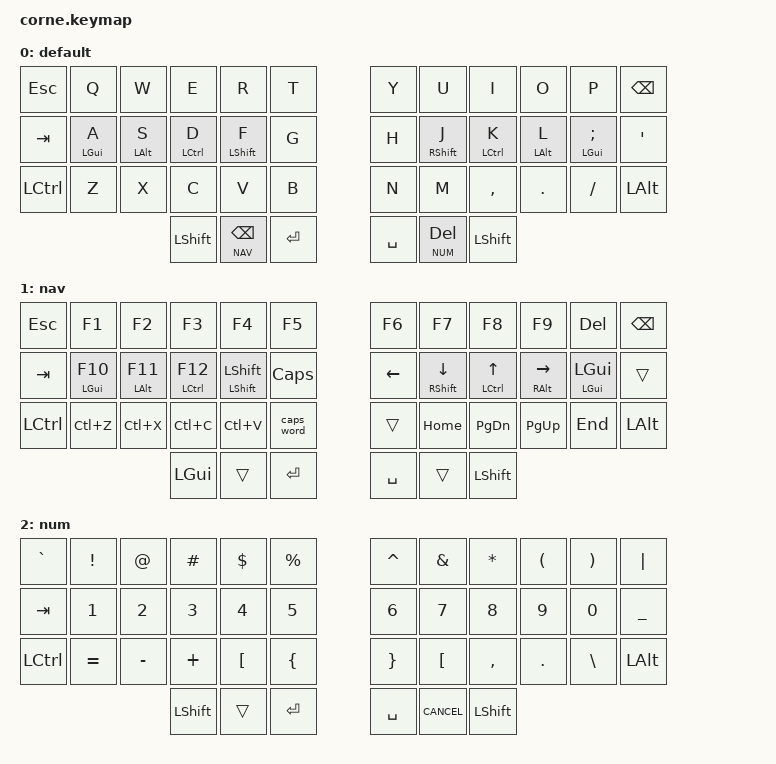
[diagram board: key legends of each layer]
/*
 * Copyright (c) 2020 The ZMK Contributors
 *
 * SPDX-License-Identifier: MIT
 */

#include <behaviors.dtsi>
#include <dt-bindings/zmk/keys.h>
#include <dt-bindings/zmk/bt.h>
#define _BT_SEL_KEYS_ &bt BT_SEL 0 &bt BT_SEL 1 &bt BT_SEL 2 &bt BT_SEL 3 &bt BT_CLR

#include "../zmk-nodefree-config/helper.h"
#include "../zmk-nodefree-config/keypos_def/keypos_42keys.h"
#include "../zmk-nodefree-config/international_chars/german.dtsi"

#define DEF 0
#define NAV 1
#define NUM 2
#define SYS 3

/*#include "combos.dtsi"  // requires layer aliases*/
/*#include "extra_keys.h"*/

/*layers and shortcuts*/
#define XXX &none
#define ___ &trans

/* Global settings */

#define QUICK_TAP_MS 175

&sk {  // sticky-key config
    release-after-ms = <900>;  // release after 0.6s
    quick-release;             // no double capitalization when rolling keys
};

&sl {  // sticky-layer config
    ignore-modifiers;          // allow chording sticky mods & layers
};

&lt {  // layer-tap config
    flavor = "balanced";
    tapping-term-ms = <200>;
    quick-tap-ms = <QUICK_TAP_MS>;
};

/*custom behaviors*/

// homerow mods
#define KEYS_L LT0 LT1 LT2 LT3 LT4 LT5 LM0 LM1 LM2 LM3 LM4 LM5 LB0 LB1 LB2 LB3 LB4 LB5  // left hand
#define KEYS_R RT0 RT1 RT2 RT3 RT4 RT5 RM0 RM1 RM2 RM3 RM4 RM5 RB0 RB1 RB2 RB3 RB4 RM5  // right hand
#define THUMBS LH2 LH1 LH0 RH0 RH1 RH2                                      // thumbs

#define MAKE_HRM(NAME, HOLD, TAP, TRIGGER_POS) \
    ZMK_BEHAVIOR(NAME, hold_tap, \
        flavor = "balanced"; \
        tapping-term-ms = <280>; \
        quick-tap-ms = <QUICK_TAP_MS>; \
        global-quick-tap-ms = <150>; \
        bindings = <HOLD>, <TAP>; \
        hold-trigger-key-positions = <TRIGGER_POS>; \
        hold-trigger-on-release; \
    )
MAKE_HRM(hml, &kp, &kp, KEYS_R THUMBS)  // left-hand HRMs
MAKE_HRM(hmr, &kp, &kp, KEYS_L THUMBS)  // right-hand HRMs

/*MAKE_HRM(hml_repeat, &kp, &key_repeat, KEYS_R THUMBS)  // used for HRM-combo*/
/*MAKE_HRM(hmr_lpar_lt, &kp, &lpar_lt, KEYS_L THUMBS)    // "    "   "   "*/
/*MAKE_HRM(hmr_rpar_gt, &kp, &rpar_gt, KEYS_L THUMBS)    // "    "   "   "*/


// tap: backspace | shift + tap: delete | hold: num layer
/*ZMK_BEHAVIOR(bs_del_num, mod_morph,*/
    /*bindings = <&lt NUM BSPC>, <&kp DEL>;*/
    /*mods = <(MOD_LSFT|MOD_RSFT)>;*/
/*)*/

/* Caps-word, num-word */

// tap: sticky-shift | shift + tap/ double-tap: caps-word | hold: shift
/*ZMK_BEHAVIOR(smart_shft, mod_morph,*/
    /*bindings = <&sk LSHFT>, <&caps_word>;*/
    /*mods = <(MOD_LSFT)>;*/
/*)*/
/*&caps_word {  // mods deactivate caps-word, requires PR #1451*/
    /*/delete-property/ ignore-modifiers;*/
/*};*/

// tap: num-word | double-tap: sticky num-layer | hold: num-layer
/*#define SMART_NUM &smart_num NUM 0*/
/*ZMK_BEHAVIOR(smart_num, hold_tap,*/
    /*flavor = "balanced";*/
    /*tapping-term-ms = <200>;*/
    /*quick-tap-ms = <QUICK_TAP_MS>;*/
    /*bindings = <&mo>, <&num_dance>;*/
/*)*/
/*ZMK_BEHAVIOR(num_dance, tap_dance,*/
    /*tapping-term-ms = <200>;*/
    /*bindings = <&num_word>, <&sl NUM>;  // reverse this for sticky-num on single tap*/
/*)*/
/*&num_word {  // num-word, requires PR #1451*/
    /*layers = <NUM>;*/
    /*continue-list = <BSPC DEL DOT COMMA PLUS MINUS STAR FSLH EQUAL>;*/
/*};*/

// Sticky layer + sticky shift (workaround for issue #1421)
/*ZMK_BEHAVIOR(sls, sticky_key,*/
    /*release-after-ms = <1000>;*/
    /*bindings = <&uc_shift>;*/
    /*ignore-modifiers;*/
/*)*/
/*ZMK_BEHAVIOR(uc_shift, macro,*/
    /*wait-ms = <0>;*/
    /*tap-ms = <1>;*/
    /*bindings = <&macro_press &mo UC &kp LSHFT>*/
             /*, <&macro_pause_for_release>*/
             /*, <&macro_release &mo UC &kp LSHFT>;*/
/*)*/

// Alt+Tab swapper, requires PR #1366
/*ZMK_BEHAVIOR(swapper, tri_state,*/
    /*bindings = <&kt LALT>, <&kp TAB>, <&kt LALT>;*/
    /*ignored-key-positions = <LT2>;*/
/*)*/

/*#undef COMBO_TERM*/
/*#define COMBO_TERM 40  // timeout of 40ms (default is 30ms if omitted)*/
/*ZMK_COMBO(combo_copy,   &kp LC(C),  LB2 LB3, ALL)  // Ctrl + C, active on all layers*/
/*ZMK_COMBO(combo_paste,  &kp LC(V),  LB1 LB2, ALL)  // Ctrl + V, active on all layers*/

/* Keymap */

ZMK_CONDITIONAL_LAYER(NAV NUM, SYS)  // NAV + SYM --> SYS

ZMK_LAYER(default,
     // ╭─────────────┬─────────────┬─────────────┬─────────────┬─────────────┬─────────────╮   ╭─────────────┬─────────────┬─────────────┬─────────────┬─────────────┬─────────────╮
          &kp ESC         &kp Q         &kp W         &kp E         &kp R           &kp T            &kp Y         &kp U         &kp I         &kp O         &kp P       &kp BSPC
     // ├─────────────┼─────────────┼─────────────┬─────────────┼─────────────┼─────────────┤   ├─────────────┬─────────────┼─────────────┼─────────────┼─────────────┼─────────────┤
          &kp TAB       &hml LGUI A   &hml LALT S   &hml LCTRL D  &hml LSHFT F     &kp G             &kp H     &hmr RSHFT J  &hmr LCTRL K  &hmr LALT L   &hmr LGUI SEMI  &kp SQT
     // ├─────────────┼─────────────┼─────────────┬─────────────┼─────────────┼─────────────┤   ├─────────────┬─────────────┼─────────────┼─────────────┼─────────────┼─────────────┤
          &kp LCTRL         &kp Z         &kp X         &kp C         &kp V        &kp B             &kp N         &kp M       &kp COMMA      &kp DOT      &kp FSLH      &kp LALT
     // ╰─────────────┼─────────────┼─────────────┬─────────────┼─────────────┼─────────────┤   ├─────────────┬─────────────┼─────────────┼─────────────┼─────────────┼─────────────┤
                                                   &kp LSHIFT    &lt NAV BSPC    &kp RET           &kp SPACE    &lt NUM DEL  &kp LSHIFT
     //                                           ╰─────────────┴─────────────┴─────────────╯   ╰─────────────┴─────────────┴─────────────╯
)

ZMK_LAYER(nav,
     // ╭─────────────┬─────────────┬─────────────┬─────────────┬─────────────┬─────────────╮   ╭─────────────┬─────────────┬─────────────┬─────────────┬─────────────┬─────────────╮
          &kp ESC         &kp F1        &kp F2       &kp F3         &kp F4        &kp F5            &kp F6        &kp F7        &kp F8        &kp F9         &kp DEL      &kp BSPC
     // ├─────────────┼─────────────┼─────────────┬─────────────┼─────────────┼─────────────┤   ├─────────────┬─────────────┼─────────────┼─────────────┼─────────────┼─────────────┤
          &kp TAB      &hml LGUI F10 &hml LALT F11 &hml LCTRL F12 &hml LSHFT LSHIFT &kp CAPS     &kp LEFT      &hmr RSHFT DOWN &hmr LCTRL UP &hmr RALT RIGHT &hmr LGUI LGUI   ___ 
     // ├─────────────┼─────────────┼─────────────┬─────────────┼─────────────┼─────────────┤   ├─────────────┬─────────────┼─────────────┼─────────────┼─────────────┼─────────────┤
          &kp LCTRL      &kp LC(Z)     &kp LC(X)    &kp LC(C)      &kp LC(V)    &caps_word             ___       &kp HOME    &kp PAGE_DOWN &kp PAGE_UP      &kp END      &kp LALT
     // ╰─────────────┼─────────────┼─────────────┬─────────────┼─────────────┼─────────────┤   ├─────────────┬─────────────┼─────────────┼─────────────┼─────────────┼─────────────┤
                                                     &kp LGUI         ___         &kp RET           &kp SPACE       ___       &kp LSHIFT
     //                                           ╰─────────────┴─────────────┴─────────────╯   ╰─────────────┴─────────────┴─────────────╯
)

ZMK_LAYER(num,
     // ╭─────────────┬─────────────┬─────────────┬─────────────┬─────────────┬─────────────╮   ╭─────────────┬─────────────┬─────────────┬─────────────┬─────────────┬─────────────╮
          &kp GRAVE      &kp EXCL      &kp AT        &kp HASH      &kp DLLR      &kp PRCNT         &kp CARET     &kp AMPS   &kp ASTRK       &kp LPAR      &kp RPAR       &kp PIPE
     // ├─────────────┼─────────────┼─────────────┬─────────────┼─────────────┼─────────────┤   ├─────────────┬─────────────┼─────────────┼─────────────┼─────────────┼─────────────┤
          &kp TAB       &kp N1           &kp N2       &kp N3        &kp N4        &kp N5             &kp N6       &kp N7        &kp N8        &kp N9       &kp N0        &kp UNDER
     // ├─────────────┼─────────────┼─────────────┬─────────────┼─────────────┼─────────────┤   ├─────────────┬─────────────┼─────────────┼─────────────┼─────────────┼─────────────┤
          &kp LCTRL    &kp EQUAL       &kp MINUS    &kp PLUS       &kp LBKT     &kp LBRC          &kp RBRC      &kp LBKT      &kp COMMA      &kp DOT      &kp BSLH      &kp LALT
     // ╰─────────────┼─────────────┼─────────────┬─────────────┼─────────────┼─────────────┤   ├─────────────┬─────────────┼─────────────┼─────────────┼─────────────┼─────────────┤
                                                   &kp LSHIFT         ___        &kp RET           &kp SPACE      CANCEL      &kp LSHIFT
     //                                           ╰─────────────┴─────────────┴─────────────╯   ╰─────────────┴─────────────┴─────────────╯
)

/*ZMK_LAYER(sys,*/
     /*// ╭─────────────┬─────────────┬─────────────┬─────────────┬─────────────┬─────────────╮   ╭─────────────┬─────────────┬─────────────┬─────────────┬─────────────┬─────────────╮*/
          /*&kp ESC      &bt BT_SEL 0  &bt BT_SEL 1  &bt BT_SEL 2       ___          ___               ___           ___            ___          ___           ___           ___*/
     /*// ├─────────────┼─────────────┼─────────────┬─────────────┼─────────────┼─────────────┤   ├─────────────┬─────────────┼─────────────┼─────────────┼─────────────┼─────────────┤*/
          /*&sys_reset    &bootloader     ___           ___             ___          ___               ___           ___            ___       &kp K_LOCK    &bootloader   &sys_reset*/
     /*// ├─────────────┼─────────────┼─────────────┬─────────────┼─────────────┼─────────────┤   ├─────────────┬─────────────┼─────────────┼─────────────┼─────────────┼─────────────┤*/
             /*___       &out OUT_TOG     ___           ___             ___          ___           &kp LC(LS(M))  &kp C_MUTE    &kp C_VOL_DN  &kp C_VOL_UP    ___             ___*/
     /*// ╰─────────────┼─────────────┼─────────────┬─────────────┼─────────────┼─────────────┤   ├─────────────┬─────────────┼─────────────┼─────────────┼─────────────┼─────────────┤*/
                                                   /*&kp LSHIFT         ___        &kp RET           &kp SPACE        ___       &kp LSHIFT*/
     /*//                                           ╰─────────────┴─────────────┴─────────────╯   ╰─────────────┴─────────────┴─────────────╯*/
/*)*/
